# CH32V20xxx register map
Vendor: WCH Ltd.; File version: 1.0
Registers are 32-bit, read-write, reset 0x0 unless marked. A register's access mark holds for its fields unless they carry their own. Offsets are from the block's base; [hi:lo] are bit positions; {n}, {i} and the like mark numbered series; 'fields as' and 'values as' point back to an identical list.

## SDIO — Secure digital input/output interface
Base 0x40018000
0x00 POWER — Bits 1:0 = PWRCTRL: Power supply control bits
  [1:0] PWRCTRL
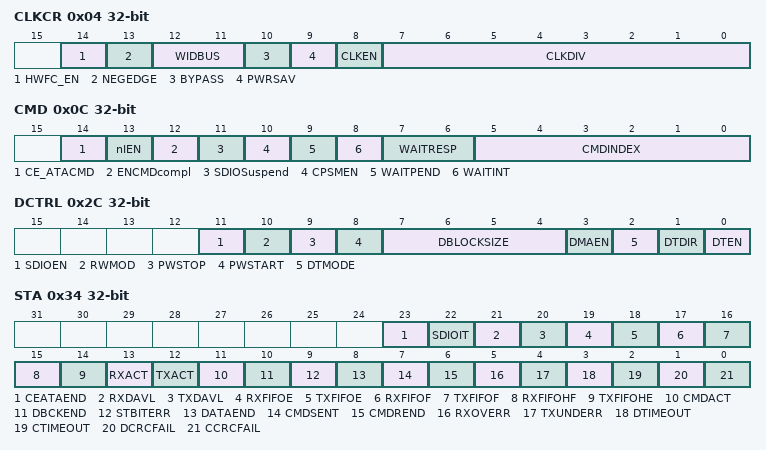
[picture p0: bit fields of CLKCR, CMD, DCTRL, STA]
0x04 CLKCR — SDI clock control register (SDIO_CLKCR)
  [14] HWFC_EN — HW Flow Control enable
  [13] NEGEDGE — SDIO_CK dephasing selection bit
  [12:11] WIDBUS — Wide bus mode enable bit
  [10] BYPASS — Clock divider bypass enable bit
  [9] PWRSAV — Power saving configuration bit
  [8] CLKEN — Clock enable bit
  [7:0] CLKDIV — Clock divide factor
0x08 ARG — Bits 31:0 = : Command argument
  [31:0] CMDARG — Command argument
0x0C CMD — SDIO command register (SDIO_CMD)
  [14] CE_ATACMD, [13] nIEN, [12] ENCMDcompl, [11] SDIOSuspend, [10] CPSMEN, [9] WAITPEND, [8] WAITINT, [7:6] WAITRESP, [5:0] CMDINDEX
0x10 RESPCMD ro — SDIO command register
  [5:0] RESPCMD
0x14 RESPI1 ro — Bits 31:0 = CARDSTATUS1
  [31:0] CARDSTATUS1
{0x10+4i} RESP{i} ro (i=2..4) — Bits 31:0 = CARDSTATUS{i}
  [31:0] CARDSTATUS{i}
0x24 DTIMER — Bits 31:0 = DATATIME: Data timeout period
  [31:0] DATATIME — Data timeout period
0x28 DLEN — Bits 24:0 = DATALENGTH: Data length value
  [24:0] DATALENGTH — Data length value
0x2C DCTRL — SDIO data control register (SDIO_DCTRL)
  [11] SDIOEN, [10] RWMOD, [9] PWSTOP, [8] PWSTART, [7:4] DBLOCKSIZE, [3] DMAEN, [2] DTMODE, [1] DTDIR, [0] DTEN
0x30 DCOUNT ro — Bits 24:0 = DATACOUNT: Data count value
  [24:0] DATACOUNT — Data count value
0x34 STA ro — SDIO status register (SDIO_STA)
  [23] CEATAEND, [22] SDIOIT, [21] RXDAVL, [20] TXDAVL, [19] RXFIFOE, [18] TXFIFOE, [17] RXFIFOF, [16] TXFIFOF, [15] RXFIFOHF, [14] TXFIFOHE, [13] RXACT, [12] TXACT, [11] CMDACT, [10] DBCKEND, [9] STBITERR, [8] DATAEND, [7] CMDSENT, [6] CMDREND, [5] RXOVERR, [4] TXUNDERR, [3] DTIMEOUT, [2] CTIMEOUT, [1] DCRCFAIL, [0] CCRCFAIL
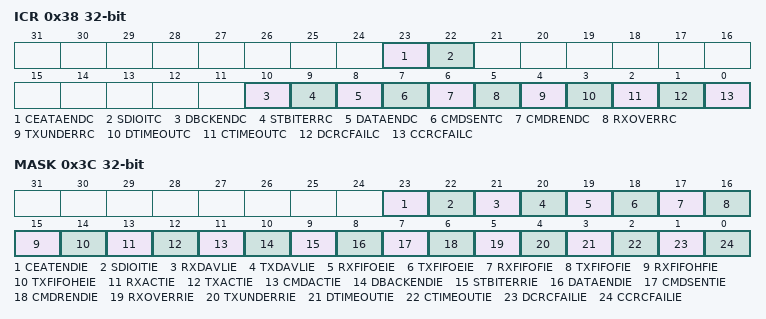
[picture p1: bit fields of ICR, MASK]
0x38 ICR — SDIO interrupt clear register (SDIO_ICR)
  [23] CEATAENDC, [22] SDIOITC, [10] DBCKENDC, [9] STBITERRC, [8] DATAENDC, [7] CMDSENTC, [6] CMDRENDC, [5] RXOVERRC, [4] TXUNDERRC, [3] DTIMEOUTC, [2] CTIMEOUTC, [1] DCRCFAILC, [0] CCRCFAILC
0x3C MASK — SDIO mask register (SDIO_MASK)
  [23] CEATENDIE, [22] SDIOITIE, [21] RXDAVLIE, [20] TXDAVLIE, [19] RXFIFOEIE, [18] TXFIFOEIE, [17] RXFIFOFIE, [16] TXFIFOFIE, [15] RXFIFOHFIE, [14] TXFIFOHEIE, [13] RXACTIE, [12] TXACTIE, [11] CMDACTIE, [10] DBACKENDIE, [9] STBITERRIE, [8] DATAENDIE, [7] CMDSENTIE, [6] CMDRENDIE, [5] RXOVERRIE, [4] TXUNDERRIE, [3] DTIMEOUTIE, [2] CTIMEOUTIE, [1] DCRCFAILIE, [0] CCRCFAILIE
0x48 FIFOCNT ro — Bits 23:0 = FIFOCOUNT: Remaining number of words to be written to or read from the FIFO
  [23:0] FIF0COUNT
0x80 FIFO — bits 31:0 = FIFOData: Receive and transmit FIFO data
  [31:0] FIFOData

## FSMC — Flexible static memory controller
Base 0xA0000000
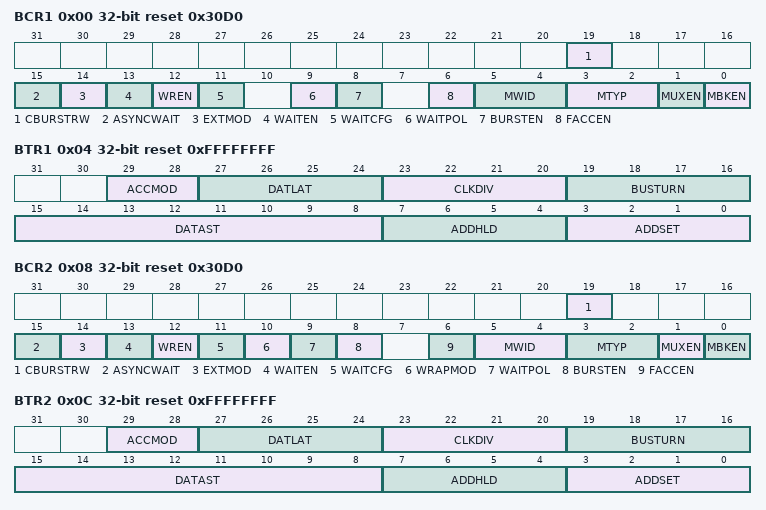
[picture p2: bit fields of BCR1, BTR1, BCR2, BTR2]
0x00 BCR1 reset 0x30D0 — SRAM/NOR-Flash chip-select control register 1
  [19] CBURSTRW, [15] ASYNCWAIT, [14] EXTMOD, [13] WAITEN, [12] WREN, [11] WAITCFG, [9] WAITPOL, [8] BURSTEN, [6] FACCEN, [5:4] MWID, [3:2] MTYP, [1] MUXEN, [0] MBKEN
0x04 BTR1 reset 0xFFFFFFFF — SRAM/NOR-Flash chip-select timing register 1
  [29:28] ACCMOD, [27:24] DATLAT, [23:20] CLKDIV, [19:16] BUSTURN, [15:8] DATAST, [7:4] ADDHLD, [3:0] ADDSET
0x08 BCR2 reset 0x30D0 — SRAM/NOR-Flash chip-select control register 2
  [19] CBURSTRW, [15] ASYNCWAIT, [14] EXTMOD, [13] WAITEN, [12] WREN, [11] WAITCFG, [10] WRAPMOD, [9] WAITPOL, [8] BURSTEN, [6] FACCEN, [5:4] MWID, [3:2] MTYP, [1] MUXEN, [0] MBKEN
0x0C BTR2 reset 0xFFFFFFFF — SRAM/NOR-Flash chip-select timing register 2
  fields as BTR1
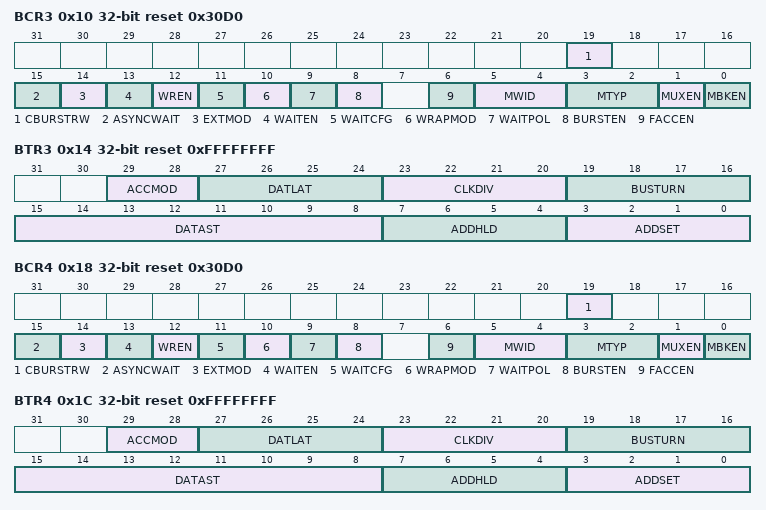
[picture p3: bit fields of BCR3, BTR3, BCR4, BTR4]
0x10 BCR3 reset 0x30D0 — SRAM/NOR-Flash chip-select control register 3
  fields as BCR2
0x14 BTR3 reset 0xFFFFFFFF — SRAM/NOR-Flash chip-select timing register 3
  fields as BTR1
0x18 BCR4 reset 0x30D0 — SRAM/NOR-Flash chip-select control register 4
  fields as BCR2
0x1C BTR4 reset 0xFFFFFFFF — SRAM/NOR-Flash chip-select timing register 4
  fields as BTR1
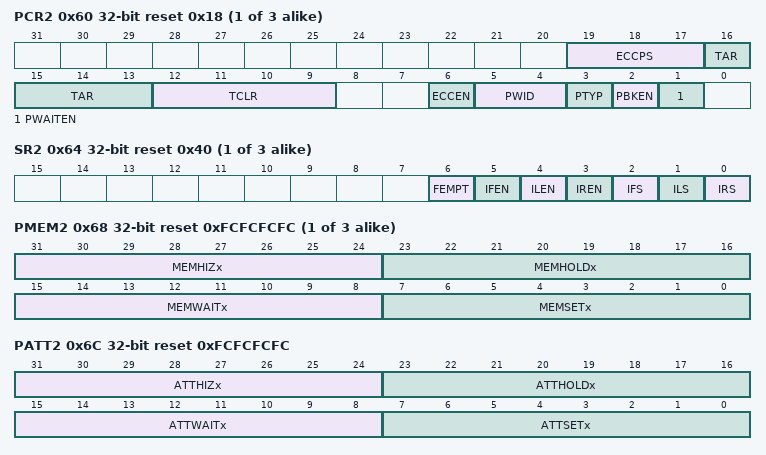
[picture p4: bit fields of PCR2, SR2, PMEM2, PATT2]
{0x20+0x20*i} PCR{i} reset 0x18 (i=2..4) — PC Card/NAND Flash control register {i}
  [19:17] ECCPS, [16:13] TAR, [12:9] TCLR, [6] ECCEN, [5:4] PWID, [3] PTYP, [2] PBKEN, [1] PWAITEN
{0x24+0x20*i} SR{i} access per field reset 0x40 (i=2..4) — FIFO status and interrupt register {i}
  [6] FEMPT ro, [5] IFEN rw, [4] ILEN rw, [3] IREN rw, [2] IFS rw, [1] ILS rw, [0] IRS rw
{0x28+0x20*i} PMEM{i} reset 0xFCFCFCFC (i=2..4) — Common memory space timing register {i}
  [31:24] MEMHIZx, [23:16] MEMHOLDx, [15:8] MEMWAITx, [7:0] MEMSETx
0x6C PATT2 reset 0xFCFCFCFC — Attribute memory space timing register 2
  [31:24] ATTHIZx — Attribute memory x databus HiZ time
  [23:16] ATTHOLDx — Attribute memory x hold time
  [15:8] ATTWAITx — Attribute memory x wait time
  [7:0] ATTSETx — Attribute memory x setup time
0x74 ECCR2 ro — ECC result register 2
  [31:0] ECCx — ECC result
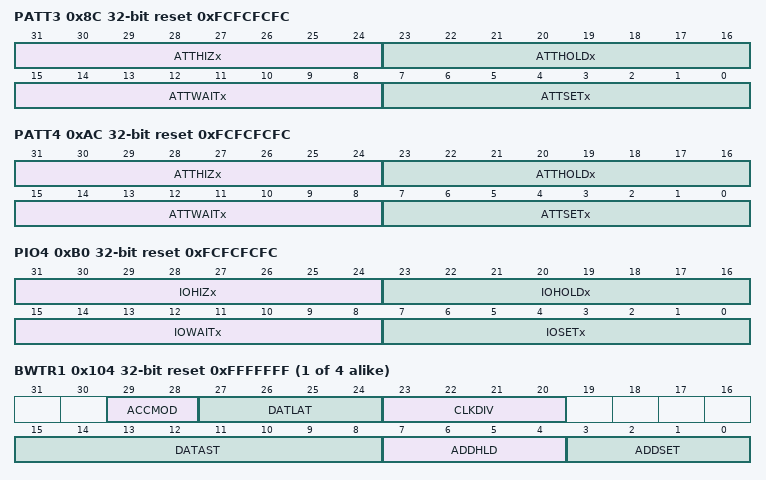
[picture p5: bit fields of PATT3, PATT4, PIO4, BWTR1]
0x8C PATT3 reset 0xFCFCFCFC — Attribute memory space timing register 3
  [31:24] ATTHIZx, [23:16] ATTHOLDx, [15:8] ATTWAITx, [7:0] ATTSETx
0x94 ECCR3 ro — ECC result register 3
  [31:0] ECCx
0xAC PATT4 reset 0xFCFCFCFC — Attribute memory space timing register 4
  [31:24] ATTHIZx, [23:16] ATTHOLDx, [15:8] ATTWAITx, [7:0] ATTSETx
0xB0 PIO4 reset 0xFCFCFCFC — I/O space timing register 4
  [31:24] IOHIZx, [23:16] IOHOLDx, [15:8] IOWAITx, [7:0] IOSETx
{0xFC+8i} BWTR{i} reset 0xFFFFFFF (i=1..4) — SRAM/NOR-Flash write timing registers {i}
  [29:28] ACCMOD, [27:24] DATLAT, [23:20] CLKDIV, [15:8] DATAST, [7:4] ADDHLD, [3:0] ADDSET
